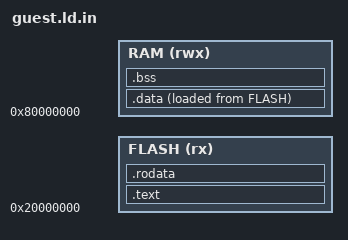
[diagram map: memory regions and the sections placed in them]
/* SPDX-License-Identifier: Apache-2.0 */
/*
 * guest.ld - Link script for RV32 guest images.
 *
 * Generated from guest.ld.in: LENGTH is substituted from
 * EMU_GUEST_RAM_KIB so it always matches the RAM the emulator actually
 * maps at RV_GUEST_RAM_BASE. Getting this wrong is not a link error --
 * _stack_top simply ends up past the end of guest RAM, and the guest takes
 * a store access fault on its first push, before it has installed a trap
 * handler that could report it.
 *
 * The layout is a microcontroller's: .text and .rodata in flash, .data
 * and .bss in RAM, and .data's initialiser at a load address in flash for
 * start.S to copy across. The flat binary objcopy produces is therefore
 * mapped at EMU_GUEST_ROM_BASE and entered at offset 0.
 */

OUTPUT_ARCH(riscv)
ENTRY(_start)

/*
 * Two regions, laid out the way a microcontroller is: code and constants
 * execute from flash, writable data lives in RAM, and `.data`'s
 * initialiser sits in flash to be copied at start-up.
 *
 * FLASH is the image, mapped read-only by every platform at
 * EMU_GUEST_ROM_BASE and served straight out of the host's own flash
 * where there is one -- so it costs the guest no RAM at all, however
 * large it is. That is what lets an architecture test needing 345 KiB
 * run on a part with 264 KiB of guest RAM.
 *
 * Its size is a *link-time bound*, not a mapping: the host maps
 * whatever the image turns out to be, and a board serves it from its own
 * flash. 16 MiB is plenty for every guest here except one -- Quake
 * carries an 18.7 MiB PAK in .rodata -- so it is a variable rather than
 * a constant, raised by the recipe that needs it.
 *
 * **The emulator does not need to know where the boundary is.** It used
 * to: the image was split at __guest_ro_end and the two halves uploaded
 * separately, which is how the board learned where to stop serving flash
 * and start serving RAM. With the run addresses in separate regions
 * there is nothing to infer -- flash is flash and RAM is RAM -- and an
 * upload is one blob.
 */
MEMORY
{
    FLASH (rx)  : ORIGIN = 0x20000000, LENGTH = @EMU_GUEST_ROM_MIB@M
    RAM   (rwx) : ORIGIN = 0x80000000, LENGTH = @EMU_GUEST_RAM_KIB@K
}

SECTIONS
{
    .text : ALIGN(4)
    {
        KEEP(*(.text.init))     /* _start must be first: entry is at +0 */
        *(.text .text.*)
    } > FLASH

    .rodata : ALIGN(4)
    {
        *(.rodata .rodata.*)
        *(.srodata .srodata.*)
        /*
         * Unwind tables, named here so they land inside the read-only
         * half rather than in an output section of their own. No guest
         * unwinds, but the toolchain's library objects carry them: the
         * linker's default placement put .eh_frame between .rodata and
         * .data, where it is in the flat binary and in *neither* half of
         * the split -- which the build's cat-and-compare caught the first
         * time a guest linked against newlib. Discarding them instead
         * would work equally well for the split and would leave the ELF
         * unable to unwind under gdb.
         */
        *(.eh_frame .eh_frame.*)
        /*
         * Inside the section, not after it, so that .rodata's own extent
         * is padded and .data's load address starts aligned.
         *
         * An ALIGN *between* output sections looks equivalent and is
         * not: it moves the location counter while leaving the section's
         * extent unchanged, so `objcopy -j .text -j .rodata` emits bytes
         * only up to the end of its contents. That is what made the old
         * two-piece image lossy -- hello came out 393 + 4 against a
         * 400-byte binary, and the three missing bytes put .data below
         * where the guest read it. The guest ran anyway, on zeros.
         */
        . = ALIGN(4);
    } > FLASH

    .data : ALIGN(4)
    {
        __data_start = .;
        *(.data .data.*)
        /*
         * __global_pointer$ addresses the middle of the small-data area so
         * a signed 12-bit offset from gp reaches all of it.
         */
        . = ALIGN(8);
        PROVIDE(__global_pointer$ = . + 0x800);
        *(.sdata .sdata.*)

        /*
         * Thread-local storage, which a single-threaded bare-metal
         * guest still has: **picolibc keeps errno and the
         * random-number state in it**, so a guest that touches either
         * with tp unset faults near address 0 -- and with no trap
         * handler that is a silent spin.
         *
         * .tdata goes *inside* .data and .tbss at the head of .bss,
         * rather than in output sections of their own. Two reasons,
         * and the second cost a working build: they have to be
         * contiguous and in this order, because the compiler addresses
         * both as offsets from one base; and the symbols bounding the
         * copy and the zero have to stay in the sections that are
         * actually copied and zeroed. Given their own sections, an
         * *empty* .tbss was placed before an ALIGN'd .tdata, which put
         * __bss_start below __data_end and broke every guest that links
         * this script.
         */
        . = ALIGN(8);
        __tls_base = .;
        *(.tdata .tdata.*)

        . = ALIGN(4);
        __data_end = .;
    } > RAM AT> FLASH

    /*
     * Where .data's initialiser lives, and where it has to end up.
     * LOADADDR is in ROM, VMA is in RAM, and start.S copies between
     * them the way any embedded crt0 does. The range it copies now
     * includes .tdata, which is inside .data above for exactly that
     * reason.
     */
    __data_lma = LOADADDR(.data);

    .bss (NOLOAD) : ALIGN(4)
    {
        __bss_start = .;
        /* Immediately after .tdata, and zeroed with the rest: see above. */
        *(.tbss .tbss.*)
        *(.sbss .sbss.*)
        *(.bss .bss.*)
        *(COMMON)
        . = ALIGN(4);
        __bss_end = .;
    } > RAM

    . = ALIGN(16);
    _end = .;

    /* Stack grows down from the top of RAM. */
    _stack_top = ORIGIN(RAM) + LENGTH(RAM);

    /DISCARD/ : { *(.comment) *(.note.*) *(.riscv.attributes) }
}
